AUTOSAR XML (schema 4-0-3)
standard types defined: Boolean, UInt8
package /AUTOSAR_Platform/DataConstrs
  range DC_Boolean: raw 0..1
package /PATAC/Facility/DataTypes/Implementation
  unit NoUnit: factor-si-to-unit=1, offset-si-to-unit=0
package /PATAC/MSM/ComponentTypes
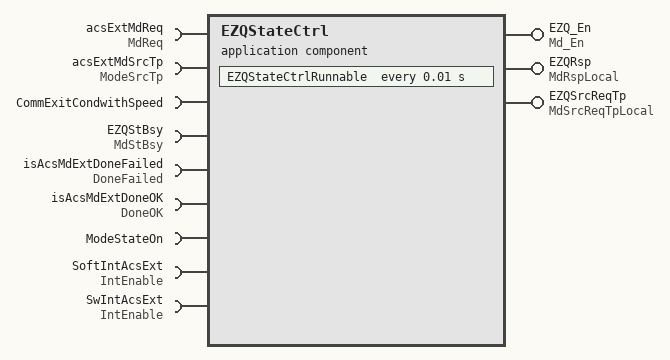
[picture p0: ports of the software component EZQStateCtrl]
  application sw component type EZQStateCtrl
    provide port EZQ_En: nonqueued-sender-com-spec{data-element=Md_En/Val, init-value=0}, provided-interface=Md_En
    provide port EZQRsp: nonqueued-sender-com-spec{data-element=MdRspLocal/Val, init-value=0}, provided-interface=MdRspLocal
    provide port EZQSrcReqTp: nonqueued-sender-com-spec{data-element=MdSrcReqTpLocal/Val, init-value=0}, provided-interface=MdSrcReqTpLocal
    9 x require port:
      acsExtMdReq: nonqueued-receiver-com-spec{data-element=MdReq/Val, filter=data-filter-type=ALWAYS, init-value=0}, required-interface=MdReq
      acsExtMdSrcTp: nonqueued-receiver-com-spec{data-element=ModeSrcTp/Val, filter=data-filter-type=ALWAYS, init-value=0}, required-interface=ModeSrcTp
      CommExitCondwithSpeed: nonqueued-receiver-com-spec{data-element=CommExitCondwithSpeed/Val, filter=data-filter-type=ALWAYS, init-value=0}, required-interface=CommExitCondwithSpeed
      EZQStBsy: nonqueued-receiver-com-spec{data-element=MdStBsy/Val, filter=data-filter-type=ALWAYS, init-value=0}, required-interface=MdStBsy
      isAcsMdExtDoneFailed: nonqueued-receiver-com-spec{data-element=DoneFailed/Val, filter=data-filter-type=ALWAYS, init-value=0}, required-interface=DoneFailed
      isAcsMdExtDoneOK: nonqueued-receiver-com-spec{data-element=DoneOK/Val, filter=data-filter-type=ALWAYS, init-value=0}, required-interface=DoneOK
      ModeStateOn: nonqueued-receiver-com-spec{data-element=ModeStateOn/Val, filter=data-filter-type=ALWAYS, init-value=0}, required-interface=ModeStateOn
      SoftIntAcsExt: nonqueued-receiver-com-spec{data-element=IntEnable/Val, filter=data-filter-type=ALWAYS, init-value=0}, required-interface=IntEnable
      SwIntAcsExt: nonqueued-receiver-com-spec{data-element=IntEnable/Val, filter=data-filter-type=ALWAYS, init-value=0}, required-interface=IntEnable
    behavior EZQStateCtrl_InternalBehavior
      timing event TMT_EZEStateCtrlRunnable: start-on-event=EZQStateCtrlRunnable, period=0.01
      runnable EZQStateCtrlRunnable
        data-receive-point-by-arguments:
          9 x access:
            REC_acsExtMdReq_Val: accessed-variable=acsExtMdReq.Val
            REC_acsExtMdSrcTp_Val: accessed-variable=acsExtMdSrcTp.Val
            REC_CommExitCondwithSpeed_Val: accessed-variable=CommExitCondwithSpeed.Val
            REC_EZEStBsy_Val: accessed-variable=EZQStBsy.Val
            REC_isAcsMdExtDoneFailed_Val: accessed-variable=isAcsMdExtDoneFailed.Val
            REC_isAcsMdExtDoneOK_Val: accessed-variable=isAcsMdExtDoneOK.Val
            REC_ModeStateOn_Val: accessed-variable=ModeStateOn.Val
            REC_SoftIntAcsExt_Val: accessed-variable=SoftIntAcsExt.Val
            REC_SwIntAcsExt_Val: accessed-variable=SwIntAcsExt.Val
        data-send-points:
          access SEND_EZQ_En_Val: accessed-variable=EZQ_En.Val
          access SEND_EZQRsp_Val: accessed-variable=EZQRsp.Val
          access SEND_EZQSrcReqTp_Val: accessed-variable=EZQSrcReqTp.Val
  swc implementation EZQStateCtrl_Implementation: behavior=EZQStateCtrl_InternalBehavior
    code-descriptors:
      code Default: artifact-descriptors=autosar-engineering-object={short-label=Default, category=SWSRC}
package /PATAC/MSM/DataTypes/ImplementationDataTypes
  impl type IntEnable: category=VALUE, base-type=Boolean, sw-calibration-access=READ-ONLY, type-emitter=RTE
package /PATAC/MSM/ModeAdjust/DataType
  impl type MdRspLocal1: category=VALUE, base-type=UInt8, sw-calibration-access=READ-ONLY, compu {0=MdRsp_None, 1=MdRsp_RecallSuccessfully, 2=MdRsp_RecallUnsuccessfully_LocalInterrupt, 3=MdRsp_RecallUnsuccessfully_Error, 4=MdRsp_RecallOngoing, 5=MdRsp_RecallHalt}, type-emitter=RTE
  impl type SrcReqTp1: category=VALUE, base-type=UInt8, sw-calibration-access=READ-ONLY, compu {0=SrcReqTp_None, 1=SrcReqTp_Local, 2=SrcReqTp_HMI2L, 3=SrcReqTp_HMI2R, 4=SrcReqTp_HMI, 5=SrcReqTp_Remote, 6=SrcReqTp_SRS}, type-emitter=RTE
package /PATAC/MSM/ModeAdjust/PortInterface
  11 x sender receiver interface:
    CommExitCondwithSpeed: invalidation-policy{data-element=CommExitCondwithSpeed/Val, handle-invalid=DONT-INVALIDATE}
      data Val: type=Boolean
    DoneFailed: invalidation-policy{data-element=DoneFailed/Val, handle-invalid=DONT-INVALIDATE}
      data Val: type=Boolean
    DoneOK: invalidation-policy{data-element=DoneOK/Val, handle-invalid=DONT-INVALIDATE}
      data Val: type=Boolean
    IntEnable: invalidation-policy{data-element=IntEnable/Val, handle-invalid=DONT-INVALIDATE}
      data Val: type=IntEnable
    Md_En: invalidation-policy{data-element=Md_En/Val, handle-invalid=DONT-INVALIDATE}
      data Val: type=Boolean
    MdReq: invalidation-policy{data-element=MdReq/Val, handle-invalid=DONT-INVALIDATE}
      data Val: type=Boolean
    MdRspLocal: invalidation-policy{data-element=MdRspLocal/Val, handle-invalid=DONT-INVALIDATE}
      data Val: type=MdRspLocal1
    MdSrcReqTpLocal: invalidation-policy{data-element=MdSrcReqTpLocal/Val, handle-invalid=DONT-INVALIDATE}
      data Val: type=SrcReqTp1
    MdStBsy: invalidation-policy{data-element=MdStBsy/Val, handle-invalid=DONT-INVALIDATE}
      data Val: type=Boolean
    ModeSrcTp: invalidation-policy{data-element=ModeSrcTp/Val, handle-invalid=DONT-INVALIDATE}
      data Val: type=SrcReqTp1
    ModeStateOn: invalidation-policy{data-element=ModeStateOn/Val, handle-invalid=DONT-INVALIDATE}
      data Val: type=Boolean
